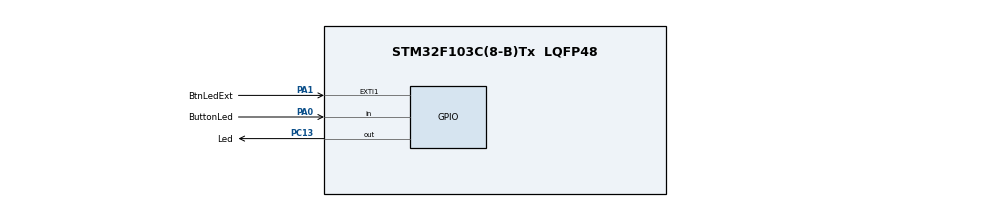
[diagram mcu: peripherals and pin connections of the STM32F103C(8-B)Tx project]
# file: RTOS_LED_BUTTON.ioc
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Mcu.Family=STM32F1
PC15-OSC32_OUT.Mode=LSE-External-Oscillator
FREERTOS.Tasks01=defaultTask,24,128,StartDefaultTask,Default,NULL,Dynamic,NULL,NULL
PD1-OSC_OUT.Mode=HSE-External-Oscillator
PC13-TAMPER-RTC.Signal=GPIO_Output
PD0-OSC_IN.Signal=RCC_OSC_IN
PC14-OSC32_IN.Signal=RCC_OSC32_IN
ProjectManager.StackSize=0x400
PA0-WKUP.GPIO_Label=ButtonLed
PA0-WKUP.Signal=GPIO_Input
VP_FREERTOS_VS_CMSIS_V2.Mode=CMSIS_V2
PD1-OSC_OUT.Signal=RCC_OSC_OUT
PA13.Signal=SYS_JTMS-SWDIO
NVIC.EXTI1_IRQn=true\:5\:0\:true\:false\:true\:false\:true\:true
VP_SYS_VS_tim3.Mode=TIM3
ProjectManager.TargetToolchain=STM32CubeIDE
PC15-OSC32_OUT.Signal=RCC_OSC32_OUT
PA1.GPIO_PuPd=GPIO_PULLUP
PA1.Signal=GPXTI1
PD0-OSC_IN.Mode=HSE-External-Oscillator
board=custom
PC13-TAMPER-RTC.GPIO_Label=Led
NVIC.TIM3_IRQn=true\:0\:0\:false\:false\:true\:false\:false\:true
RCC.APB2Freq_Value=8000000
PC14-OSC32_IN.Mode=LSE-External-Oscillator
PC13-TAMPER-RTC.PinState=GPIO_PIN_SET
PA14.Mode=Serial_Wire
PA1.GPIO_Label=BtnLedExt
PA13.Mode=Serial_Wire
Mcu.Name=STM32F103C(8-B)Tx
Mcu.Package=LQFP48
NVIC.TimeBase=TIM3_IRQn
NVIC.TimeBaseIP=TIM3
PA14.Signal=SYS_JTCK-SWCLK
ProjectManager.HeapSize=0x200
NVIC.PriorityGroup=NVIC_PRIORITYGROUP_4
PA0-WKUP.GPIO_PuPd=GPIO_PULLUP
RCC.APB1Freq_Value=8000000
PA1.GPIO_ModeDefaultEXTI=GPIO_MODE_IT_FALLING

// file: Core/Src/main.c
/* USER CODE BEGIN Header */
/**
  ******************************************************************************
  * @file           : main.c
  * @brief          : Main program body
  ******************************************************************************
  * @attention
  *
  * <h2><center>&copy; Copyright (c) 2021 STMicroelectronics.
  * All rights reserved.</center></h2>
  *
  * This software component is licensed by ST under BSD 3-Clause license,
  * the "License"; You may not use this file except in compliance with the
  * License. You may obtain a copy of the License at:
  *                        opensource.org/licenses/BSD-3-Clause
  *
  ******************************************************************************
  */
/* USER CODE END Header */
#include "main.h"
#include "cmsis_os.h"
#include "gpio.h"

/* USER CODE BEGIN PV */
extern uint8_t u8LedStatus;
uint8_t u8Count= 0;
/* USER CODE END PV */

void SystemClock_Config(void);
void MX_FREERTOS_Init(void);

/* USER CODE BEGIN 0 */
/* handle interrupts button pin a1 */
void HAL_GPIO_EXTI_Callback(uint16_t GPIO_Pin)
{
  /* Prevent unused argument(s) compilation warning */
  UNUSED(GPIO_Pin);
  /* handle button */
  if( GPIO_Pin == GPIO_PIN_1){
  		if( HAL_GPIO_ReadPin( GPIOA, GPIO_PIN_1 ) == 0U ){
  			HAL_Delay(5U);
  			if( HAL_GPIO_ReadPin( GPIOA, GPIO_PIN_1 ) == 0U ){
  				HAL_Delay(5U);
  				u8Count++;
  				u8LedStatus ^= 1;
  			}
  		}
  	}
}
/* USER CODE END 0 */

int main(void)
{

  /* MCU Configuration--------------------------------------------------------*/

  /* Reset of all peripherals, Initializes the Flash interface and the Systick. */
  HAL_Init();

  /* Configure the system clock */
  SystemClock_Config();

  /* Initialize all configured peripherals */
  MX_GPIO_Init();

  /* Init scheduler */
  osKernelInitialize();  /* Call init function for freertos objects (in freertos.c) */
  MX_FREERTOS_Init();
  /* Start scheduler */
  osKernelStart();

  /* We should never get here as control is now taken by the scheduler */
  /* Infinite loop */
  while (1)
  {

  }
}

void SystemClock_Config(void)
{
  RCC_OscInitTypeDef RCC_OscInitStruct = {0};
  RCC_ClkInitTypeDef RCC_ClkInitStruct = {0};

  /** Initializes the RCC Oscillators according to the specified parameters
  * in the RCC_OscInitTypeDef structure.
  */
  RCC_OscInitStruct.OscillatorType = RCC_OSCILLATORTYPE_HSI;
  RCC_OscInitStruct.HSIState = RCC_HSI_ON;
  RCC_OscInitStruct.HSICalibrationValue = RCC_HSICALIBRATION_DEFAULT;
  RCC_OscInitStruct.PLL.PLLState = RCC_PLL_NONE;
  if (HAL_RCC_OscConfig(&RCC_OscInitStruct) != HAL_OK)
  {
    Error_Handler();
  }
  /** Initializes the CPU, AHB and APB buses clocks
  */
  RCC_ClkInitStruct.ClockType = RCC_CLOCKTYPE_HCLK|RCC_CLOCKTYPE_SYSCLK
                              |RCC_CLOCKTYPE_PCLK1|RCC_CLOCKTYPE_PCLK2;
  RCC_ClkInitStruct.SYSCLKSource = RCC_SYSCLKSOURCE_HSI;
  RCC_ClkInitStruct.AHBCLKDivider = RCC_SYSCLK_DIV1;
  RCC_ClkInitStruct.APB1CLKDivider = RCC_HCLK_DIV1;
  RCC_ClkInitStruct.APB2CLKDivider = RCC_HCLK_DIV1;

  if (HAL_RCC_ClockConfig(&RCC_ClkInitStruct, FLASH_LATENCY_0) != HAL_OK)
  {
    Error_Handler();
  }
}

 /**
  * @brief  Period elapsed callback in non blocking mode
  * @note   This function is called  when TIM3 interrupt took place, inside
  * HAL_TIM_IRQHandler(). It makes a direct call to HAL_IncTick() to increment
  * a global variable "uwTick" used as application time base.
  * @param  htim : TIM handle
  * @retval None
  */
void HAL_TIM_PeriodElapsedCallback(TIM_HandleTypeDef *htim)
{
  if (htim->Instance == TIM3) {
    HAL_IncTick();
  }
}

void Error_Handler(void)
{
  __disable_irq();
  while (1)
  {
  }
}

/************************ (C) COPYRIGHT STMicroelectronics *****END OF FILE****/

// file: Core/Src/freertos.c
/* USER CODE BEGIN Header */
/**
  ******************************************************************************
  * File Name          : freertos.c
  * Description        : Code for freertos applications
  ******************************************************************************
  * @attention
  *
  * <h2><center>&copy; Copyright (c) 2021 STMicroelectronics.
  * All rights reserved.</center></h2>
  *
  * This software component is licensed by ST under Ultimate Liberty license
  * SLA0044, the "License"; You may not use this file except in compliance with
  * the License. You may obtain a copy of the License at:
  *                             www.st.com/SLA0044
  *
  ******************************************************************************
  */
/* USER CODE END Header */

#include "FreeRTOS.h"
#include "task.h"
#include "main.h"
#include "cmsis_os.h"

/* USER CODE BEGIN PD */
#define ON 		0
#define OFF 	1
/* USER CODE END PD */

/* USER CODE BEGIN Variables */
TaskHandle_t LEDTask= NULL;
TaskHandle_t BtnTask= NULL;

uint8_t u8LedStatus= OFF;
/* USER CODE END Variables */
/* Definitions for defaultTask */
osThreadId_t defaultTaskHandle;
const osThreadAttr_t defaultTask_attributes = {
  .name = "defaultTask",
  .stack_size = 128 * 4,
  .priority = (osPriority_t) osPriorityNormal,
};

/* USER CODE BEGIN FunctionPrototypes */
void LedTaskHandler( void * argument);
void BtnTaskHandler( void * argument);
/* USER CODE END FunctionPrototypes */

void StartDefaultTask(void *argument);

void MX_FREERTOS_Init(void); /* (MISRA C 2004 rule 8.1) */

void MX_FREERTOS_Init(void) {

  /* Create the thread(s) */
  /* creation of defaultTask */
  defaultTaskHandle = osThreadNew(StartDefaultTask, NULL, &defaultTask_attributes);

  /* USER CODE BEGIN RTOS_THREADS */
  /* add threads, ... */
  xTaskCreate(LedTaskHandler, "Led-Task", configMINIMAL_STACK_SIZE, NULL, osPriorityLow, &LEDTask);
  xTaskCreate(BtnTaskHandler, "Btn-Task", configMINIMAL_STACK_SIZE, NULL, osPriorityLow, &BtnTask);
  /* USER CODE END RTOS_THREADS */

}

void StartDefaultTask(void *argument)
{
  for(;;)
  {
    osDelay(1);
  }
}

/* USER CODE BEGIN Application */
void LedTaskHandler( void * argument){
	while(1){
		//vTaskDelay(1000u);
		//taskYIELD();  this func is use in manual context switching
		if( ON == u8LedStatus){
			HAL_GPIO_WritePin(GPIOC, GPIO_PIN_13 , GPIO_PIN_RESET);
		}else{
			HAL_GPIO_WritePin(GPIOC, GPIO_PIN_13 , GPIO_PIN_SET);
		}
	}
}

void BtnTaskHandler( void * argument){
	while(1){
		if( GPIO_PIN_RESET == HAL_GPIO_ReadPin(GPIOA, GPIO_PIN_0)){
			//u8LedStatus = ON;
		}else{
			//u8LedStatus = OFF;
		}
	}
}

/* USER CODE END Application */

/************************ (C) COPYRIGHT STMicroelectronics *****END OF FILE****/
